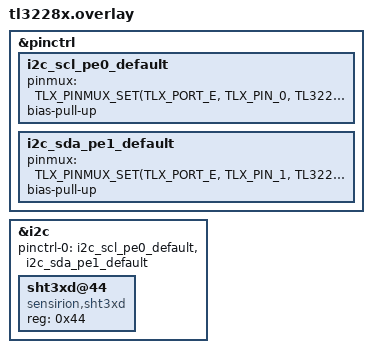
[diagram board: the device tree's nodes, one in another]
/*
 * Copyright (c) 2024 Telink Semiconductor
 *
 * SPDX-License-Identifier: Apache-2.0
 */
#include <zephyr/dt-bindings/pinctrl/tl322x-pinctrl.h>

&pinctrl {
	/* Define I2C pins: SCL(PE0), SDA(PE1) */

	i2c_scl_pe0_default: i2c_scl_pe0_default {
		pinmux = <TLX_PINMUX_SET(TLX_PORT_E, TLX_PIN_0, TL322X_FUNC_I2C_SCL_IO)>;
		bias-pull-up;
	};
	i2c_sda_pe1_default: i2c_sda_pe1_default {
		pinmux = <TLX_PINMUX_SET(TLX_PORT_E, TLX_PIN_1, TL322X_FUNC_I2C_SDA_IO)>;
		bias-pull-up;
	};
};

&i2c {
	pinctrl-0 = <&i2c_scl_pe0_default &i2c_sda_pe1_default>;

	sht3xd@44 {
		compatible = "sensirion,sht3xd";
		reg = <0x44>;
	};
};
